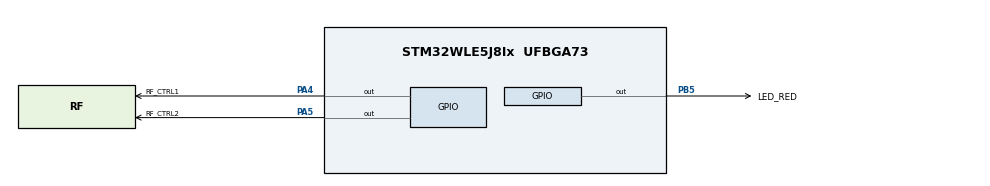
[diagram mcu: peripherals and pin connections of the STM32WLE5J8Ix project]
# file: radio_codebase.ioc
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Mcu.Family=STM32WL
Mcu.Name=STM32WLE5J8Ix
Mcu.Package=UFBGA73
NVIC.PriorityGroup=NVIC_PRIORITYGROUP_4
NVIC.SUBGHZ_Radio_IRQn=true\:1\:0\:true\:false\:true\:true\:true\:true
PA4.GPIO_Label=RF_CTRL1
PA4.PinState=GPIO_PIN_SET
PA4.Signal=GPIO_Output
PA5.GPIO_Label=RF_CTRL2
PA5.Signal=GPIO_Output
PB5.GPIO_Label=LED_RED
PB5.Signal=GPIO_Output
ProjectManager.HeapSize=0x200
ProjectManager.StackSize=0x400
ProjectManager.TargetToolchain=CMake
RCC.HSE_VALUE=8000000
RCC.HSI_VALUE=16000000
RCC.LSE_VALUE=32768
RCC.VCOOutputFreq_Value=32000000
SUBGHZ_PHY.SUBGHZ_APPLICATION=SUBGHZ_USER_APPLICATION
VP_ADV_TRACE_VS_ADV_TRACE.Mode=ADV_TRACE_Enabled
VP_MISC_VS_MISC.Mode=MISC_Enabled
VP_SEQUENCER_VS_SEQUENCER.Mode=SEQUENCER_Enabled
VP_SUBGHZ_PHY_VS_SubGhzPhy.Mode=SubGhzPhy_Enabled
VP_SUBGHZ_VS_SUBGHZ.Mode=SUBGHZ_Activate
VP_TIMER_VS_TIMER.Mode=TIMER_Enabled
VP_TINY_LPM_VS_TINY_LPM.Mode=TINY_LPM_Enabled
board=custom

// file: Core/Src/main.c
/* USER CODE BEGIN Header */
/**
  ******************************************************************************
  * @file           : main.c
  * @brief          : Main program body
  ******************************************************************************
  * @attention
  *
  * Copyright (c) 2026 STMicroelectronics.
  * All rights reserved.
  *
  * This software is licensed under terms that can be found in the LICENSE file
  * in the root directory of this software component.
  * If no LICENSE file comes with this software, it is provided AS-IS.
  *
  ******************************************************************************
  */
/* USER CODE END Header */
#include "main.h"
#include "app_subghz_phy.h"
#include "gpio.h"

/* USER CODE BEGIN Includes */
#include <string.h>

#include "radio.h"
/* USER CODE END Includes */

/* USER CODE BEGIN PV */
static RadioEvents_t RadioEvents;
volatile State_t state;
/* USER CODE END PV */

void SystemClock_Config(void);
/* USER CODE BEGIN PFP */
static void OnTxDone();
static void OnRxDone(uint8_t *payload, uint16_t size, int16_t rssi, int8_t snr);

static void OnRxTimeout();
static void OnTxTimeout();
/* USER CODE END PFP */

int main(void)
{

  /* USER CODE BEGIN 1 */
#ifdef IS_MASTER
  state = STATE_TX;
#else
  state = STATE_RX;
#endif
  /* USER CODE END 1 */

  /* MCU Configuration--------------------------------------------------------*/

  /* Reset of all peripherals, Initializes the Flash interface and the Systick. */
  HAL_Init();

  /* Configure the system clock */
  SystemClock_Config();

  /* Initialize all configured peripherals */
  MX_GPIO_Init();
  MX_SubGHz_Phy_Init();
  /* USER CODE BEGIN 2 */
  RadioEvents.TxDone = OnTxDone;
  RadioEvents.RxDone = OnRxDone;
  RadioEvents.TxTimeout = OnTxTimeout;
  RadioEvents.RxTimeout = OnRxTimeout;

  Radio.Init(&RadioEvents);

  // TODO: different values for 'Murica (possibly through a macro)
  // (possibly there is the need for an antenna for USA)
  Radio.SetChannel(868000000); // 868MHz - Standard frequency for Europe

  // TX Config: Power 14dBm, SF7, BW 125kHz, CR 4/5, Preamble 8, FixLen False, CRC On, FreqHop False, Timeout 3s
  Radio.SetTxConfig(MODEM_LORA, 14, 0, 0, 7, 1, 8,
    false, true, false, 0, false, 60000);
  // RX Config: BW 125kHz, SF7, CR 4/5, Preamble 8, Timeout 0 (Infinito), FixLen False, CRC On
  Radio.SetRxConfig(MODEM_LORA, 0, 7, 1, 0, 8,
    0, false, 0, true, false, 0, false,
    true);

  // check just to be sure
  for(int i=0; i<3; i++) {
    HAL_GPIO_TogglePin(LED_RED_GPIO_Port, LED_RED_Pin);
    HAL_Delay(500);
  }
  HAL_GPIO_WritePin(LED_RED_GPIO_Port, LED_RED_Pin, GPIO_PIN_RESET);

  /* USER CODE END 2 */

  /* Infinite loop */
  while (1)
  {
    MX_SubGHz_Phy_Process();

    /* USER CODE BEGIN 3 */
    switch (state)
    {
      case STATE_IDLE:
        {
          //HAL_GPIO_TogglePin(LED_RED_GPIO_Port, LED_RED_Pin);
          //HAL_Delay(200);
        }
        break;
      case STATE_TX:
        {
          HAL_GPIO_WritePin(LED_RED_GPIO_Port, LED_RED_Pin, GPIO_PIN_RESET);

          HAL_Delay(1000);

          char *msg;
#ifdef IS_MASTER
          msg = "PING";
#else
          msg = "PONG";
#endif
          Radio.Send((uint8_t*)msg, 4);

          state = STATE_IDLE;
        }
        break;
      case STATE_RX:
        {
          HAL_GPIO_WritePin(LED_RED_GPIO_Port, LED_RED_Pin, GPIO_PIN_SET);

          Radio.Rx(0);

          state = STATE_IDLE;
        }
        break;
    default:
      break;
    }
  }
  /* USER CODE END 3 */
}

void SystemClock_Config(void)
{
  RCC_OscInitTypeDef RCC_OscInitStruct = {0};
  RCC_ClkInitTypeDef RCC_ClkInitStruct = {0};

  /** Configure the main internal regulator output voltage
  */
  __HAL_PWR_VOLTAGESCALING_CONFIG(PWR_REGULATOR_VOLTAGE_SCALE2);

  /** Initializes the CPU, AHB and APB buses clocks
  */
  RCC_OscInitStruct.OscillatorType = RCC_OSCILLATORTYPE_MSI;
  RCC_OscInitStruct.MSIState = RCC_MSI_ON;
  RCC_OscInitStruct.MSICalibrationValue = RCC_MSICALIBRATION_DEFAULT;
  RCC_OscInitStruct.MSIClockRange = RCC_MSIRANGE_6;
  RCC_OscInitStruct.PLL.PLLState = RCC_PLL_NONE;
  if (HAL_RCC_OscConfig(&RCC_OscInitStruct) != HAL_OK)
  {
    Error_Handler();
  }

  /** Configure the SYSCLKSource, HCLK, PCLK1 and PCLK2 clocks dividers
  */
  RCC_ClkInitStruct.ClockType = RCC_CLOCKTYPE_HCLK3|RCC_CLOCKTYPE_HCLK
                              |RCC_CLOCKTYPE_SYSCLK|RCC_CLOCKTYPE_PCLK1
                              |RCC_CLOCKTYPE_PCLK2;
  RCC_ClkInitStruct.SYSCLKSource = RCC_SYSCLKSOURCE_MSI;
  RCC_ClkInitStruct.AHBCLKDivider = RCC_SYSCLK_DIV1;
  RCC_ClkInitStruct.APB1CLKDivider = RCC_HCLK_DIV1;
  RCC_ClkInitStruct.APB2CLKDivider = RCC_HCLK_DIV1;
  RCC_ClkInitStruct.AHBCLK3Divider = RCC_SYSCLK_DIV1;

  if (HAL_RCC_ClockConfig(&RCC_ClkInitStruct, FLASH_LATENCY_0) != HAL_OK)
  {
    Error_Handler();
  }
}

/* USER CODE BEGIN 4 */
void OnTxDone(void) {
  // Trasmissione finita -> Passa in ricezione
  state = STATE_RX;
}

void OnRxDone(uint8_t *payload, uint16_t size, int16_t rssi, int8_t snr)
{
  // received message
#ifdef IS_MASTER
  if (strncmp(payload, "PONG", size) || size != 4)
#else
  if (strncmp(payload, "PING", size) || size != 4)
#endif
  {
    // if received message not well-formed, light up led longer
    HAL_GPIO_WritePin(LED_RED_GPIO_Port, LED_RED_Pin, GPIO_PIN_RESET);
    HAL_Delay(500);
    HAL_GPIO_WritePin(LED_RED_GPIO_Port, LED_RED_Pin, GPIO_PIN_SET);
    HAL_Delay(250);
  }

  // we pass to transmission
  state = STATE_TX;
}

void OnTxTimeout(void) {
  // Errore? Torno in ascolto
  state = STATE_RX;
}

void OnRxTimeout(void) {
  // Non dovrebbe accadere con Rx(0), ma per sicurezza torno in ascolto
  state = STATE_RX;
}

/* USER CODE END 4 */

void Error_Handler(void)
{
  __disable_irq();
  while (1)
  {
  }
}
